# RS14100 register map
File version: 1.0
CPU: CM4 r0p1, little endian, MPU, FPU, 4 interrupt priority bits
Registers are 32-bit, read-write, reset 0x0 unless marked. A register's access mark holds for its fields unless they carry their own. Offsets are from the block's base; [hi:lo] are bit positions; {n}, {i} and the like mark numbered series; 'fields as' and 'values as' point back to an identical list.

## MCUHP_CLOCK — MCU HP (High Performance) domain contains the Cortex-M4F Processor, FPU, Debugger, MCU High Speed Interfaces, MCU HP Peripherals, MCU HP DMA and MCU/SZP shareable Interfaces
Base 0x46000000
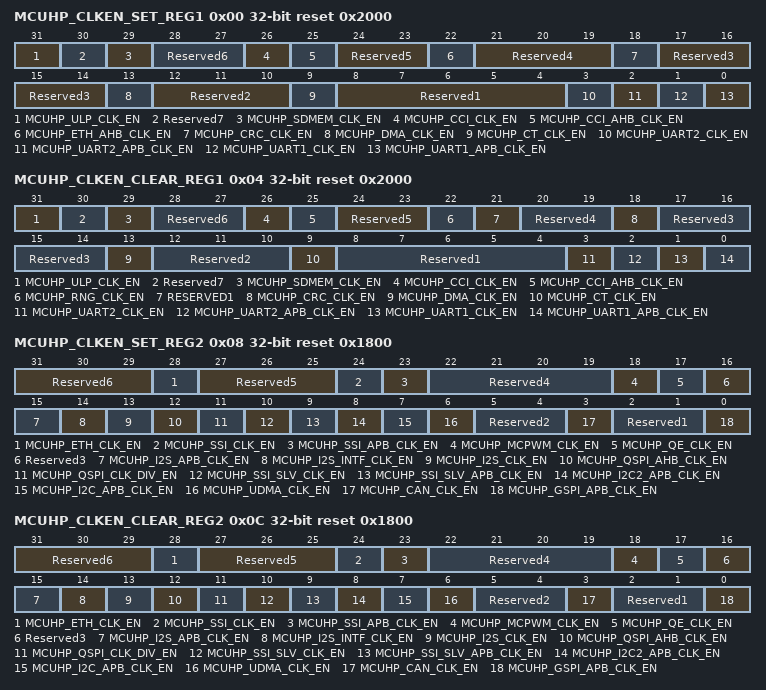
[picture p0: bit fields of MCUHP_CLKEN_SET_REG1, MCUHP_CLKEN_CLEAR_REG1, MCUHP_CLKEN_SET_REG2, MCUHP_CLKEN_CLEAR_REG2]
0x00 MCUHP_CLKEN_SET_REG1 reset 0x2000 — Clock Enable Set Register 1
  [31] MCUHP_ULP_CLK_EN wo — Writing 1 to this enables clock to MCU-ULPDomain.Writing 0 to this has no effect.
  [30] Reserved7 — It is recommended to write these bits to 0.
  [29] MCUHP_SDMEM_CLK_EN wo — Writing 1 to this enables clock to SD-MEM Controller.Writing 0 to this has no effect.
  [28:27] Reserved6 — It is recommended to write these bits to 0.
  [26] MCUHP_CCI_CLK_EN — Writing 1 to this enables clock to CCI Controller.Writing 0 to this has no effect.
  [25] MCUHP_CCI_AHB_CLK_EN — Writing 1 to this enables clock to CCI AHB Interface.Writing 0 to this has no effect.
  [24:23] Reserved5 — It is recommended to write these bits to 0.
  [22] MCUHP_ETH_AHB_CLK_EN — Writing 1 to this enables clock to Ethernet Controller AHB Interface.Writing 0 to this has no effect.
  [21:19] Reserved4 — It is recommended to write these bits to 0.
  [18] MCUHP_CRC_CLK_EN — Writing 1 to this enables clock to CRC Accelerator.Writing 0 to this has no effect.
  [17:14] Reserved3 — It is recommended to write these bits to 0.
  [13] MCUHP_DMA_CLK_EN — Writing 1 to this disables clock to DMA.Writing 0 to this has no effect.
  [12:10] Reserved2 — It is recommended to write these bits to 0.
  [9] MCUHP_CT_CLK_EN — Writing 1 to this enables clock to Configurable Timers.Writing 0 to this has no effect.
  [8:4] Reserved1 — It is recommended to write these bits to 0.
  [3] MCUHP_UART2_CLK_EN — Writing 1 to this enables clock to UART2 Controller.Writing 0 to this has no effect.
  [2] MCUHP_UART2_APB_CLK_EN — Writing 1 to this enables clock to UART2 APB Interface.Writing 0 to this has no effect.
  [1] MCUHP_UART1_CLK_EN — Writing 1 to this enables clock to UART1 Controller.Writing 0 to this has no effect.
  [0] MCUHP_UART1_APB_CLK_EN — Writing 1 to this enables clock to UART1 APB Interface.Writing 0 to this has no effect.
0x04 MCUHP_CLKEN_CLEAR_REG1 reset 0x2000 — Clock Enable Clear Register 1
  [31] MCUHP_ULP_CLK_EN — Writing 1 to this disables clock to MCU-ULPDomain.Writing 0 to this has no effect.
  [30] Reserved7 — It is recommended to write these bits to 0.
  [29] MCUHP_SDMEM_CLK_EN — Writing 1 to this disables clock to SD-MEM Controller.Writing 0 to this has no effect
  [28:27] Reserved6 — It is recommended to write these bits to 0.
  [26] MCUHP_CCI_CLK_EN — Writing 1 to this disables clock to CCI Controller.Writing 0 to this has no effect.
  [25] MCUHP_CCI_AHB_CLK_EN — Writing 1 to this disables clock to CCI AHB Interface.Writing 0 to this has no effect.
  [24:23] Reserved5 — It is recommended to write these bits to 0.
  [22] MCUHP_RNG_CLK_EN — Writing 1 to this disables clock to Random-Number-Generator.Writing 0 to this has no effect.
  [21] RESERVED1 — Writing 1 to this disables clock to Ethernet Controller AHB Interface.Writing 0 to this has no effect.
  [20:19] Reserved4 — It is recommended to write these bits to 0.
  [18] MCUHP_CRC_CLK_EN — Writing 1 to this disables clock to CRC Accelerator.Writing 0 to this has no effect.
  [17:14] Reserved3 — It is recommended to write these bits to 0.
  [13] MCUHP_DMA_CLK_EN — Writing 1 to this disables clock to DMA.Writing 0 to this has no effect
  [12:10] Reserved2 — It is recommended to write these bits to 0.
  [9] MCUHP_CT_CLK_EN — Writing 1 to this disables clock to Configurable Timers.Writing 0 to this has no effect.
  [8:4] Reserved1 — It is recommended to write these bits to 0.
  [3] MCUHP_UART2_CLK_EN — Writing 1 to this disables clock to UART2 Controller.Writing 0 to this has no effect.
  [2] MCUHP_UART2_APB_CLK_EN — Writing 1 to this disables clock to UART2 APB Interface.Writing 0 to this has no effect.
  [1] MCUHP_UART1_CLK_EN — Writing 1 to this disables clock to UART1 Controller.Writing 0 to this has no effect.
  [0] MCUHP_UART1_APB_CLK_EN — Writing 1 to this disables clock to UART1 APB Interface.Writing 0 to this has no effect.
0x08 MCUHP_CLKEN_SET_REG2 reset 0x1800 — Clock Enable Set Register 2
  [31:29] Reserved6 — It is recommended to write these bits to 0.
  [28] MCUHP_ETH_CLK_EN — Writing 1 to this enables clock to Ethernet Controller.Writing 0 to this has no effect.
  [27:25] Reserved5 — It is recommended to write these bits to 0.
  [24] MCUHP_SSI_CLK_EN — Writing 1 to this enables clock to SPI/SSI Master Controller.Writing 0 to this has no effect.
  [23] MCUHP_SSI_APB_CLK_EN — Writing 1 to this enables clock to SPI/SSI Master APN Interface.Writing 0 to this has no effect.
  [22:19] Reserved4 — It is recommended to write these bits to 0.
  [18] MCUHP_MCPWM_CLK_EN — Writing 1 to this enables clock to Motor-Control PWM.Writing 0 to this has no effect.
  [17] MCUHP_QE_CLK_EN — Writing 1 to this enables clock to Quadrature Encoder.Writing 0 to this has no effect.
  [16] Reserved3 — It is recommended to write these bits to 0.
  [15] MCUHP_I2S_APB_CLK_EN — Writing 1 to this enables clock to I2S APB Interface.Writing 0 to this has no effect.
  [14] MCUHP_I2S_INTF_CLK_EN — Writing 1 to this enables clock to I2S Interface.Writing 0 to this has no effect.
  [13] MCUHP_I2S_CLK_EN — Writing 1 to this enables clock to I2S Controller in Master Mode.Writing 0 to this has no effect.
  [12] MCUHP_QSPI_AHB_CLK_EN — Writing 1 to this enables clock to AHB Interface for SPI Flash Controller.Writing 0 to this has no effect..
  [11] MCUHP_QSPI_CLK_DIV_EN — Writing 1 to this enables clock to Clock dividers for SPI Flash Controller.Writing 0 to this has no effect.
  [10] MCUHP_SSI_SLV_CLK_EN — Writing 1 to this enables clock to SSI Slave Controller.Writing 0 to this has no effect.
  [9] MCUHP_SSI_SLV_APB_CLK_EN — Writing 1 to this enables clock to SSI Slave APB Interface.Writing 0 to this has no effect.
  [8] MCUHP_I2C2_APB_CLK_EN — Writing 1 to this enables clock to I2C-2 APB Interface.Writing 0 to this has no effect.
  [7] MCUHP_I2C_APB_CLK_EN — Writing 1 to this enables clock to I2C-1 APB Interface.Writing 0 to this has no effect.
  [6] MCUHP_UDMA_CLK_EN — Writing 1 to this enables clock to Micro-DMA.Writing 0 to this has no effect.
  [5:4] Reserved2 — It is recommended to write these bits to 0.
  [3] MCUHP_CAN_CLK_EN — Writing 1 to this enables clock to CAN Controller.Writing 0 to this has no effect.
  [2:1] Reserved1 — It is recommended to write these bits to 0
  [0] MCUHP_GSPI_APB_CLK_EN — Writing 1 to this enables clock to Generic-SPI Master APB Interface.Writing 0 to this has no effect.
0x0C MCUHP_CLKEN_CLEAR_REG2 reset 0x1800 — Clock Enable Clear Register 2
  [31:29] Reserved6 — It is recommended to write these bits to 0.
  [28] MCUHP_ETH_CLK_EN — Writing 1 to this disables clock to Ethernet Controller.Writing 0 to this has no effect.
  [27:25] Reserved5 — It is recommended to write these bits to 0.
  [24] MCUHP_SSI_CLK_EN — Writing 1 to this disables clock to SPI/SSI Master Controller.Writing 0 to this has no effect.
  [23] MCUHP_SSI_APB_CLK_EN — Writing 1 to this disables clock to SPI/SSI Master APB Interface.Writing 0 to this has no effect.
  [22:19] Reserved4 — It is recommended to write these bits to 0.
  [18] MCUHP_MCPWM_CLK_EN — Writing 1 to this disables clock to Motor-Control PWM.Writing 0 to this has no effect.
  [17] MCUHP_QE_CLK_EN — Writing 1 to this disables clock to Quadrature Encoder.Writing 0 to this has no effect.
  [16] Reserved3 — It is recommended to write these bits to 0.
  [15] MCUHP_I2S_APB_CLK_EN — Writing 1 to this disables clock to I2S APB Interface.Writing 0 to this has no effect.
  [14] MCUHP_I2S_INTF_CLK_EN — Writing 1 to this disables clock to I2S Interface.Writing 0 to this has no effect.
  [13] MCUHP_I2S_CLK_EN — Writing 1 to this disables clock to I2S Controller in Master Mode.Writing 0 to this has no effect.
  [12] MCUHP_QSPI_AHB_CLK_EN — Writing 1 to this disables clock to AHB Interface for SPI Flash Controller.Writing 0 to this has no effect.
  [11] MCUHP_QSPI_CLK_DIV_EN — Writing 1 to this disables clock to Clock dividers for SPI Flash Controller.Writing 0 to this has no effect.
  [10] MCUHP_SSI_SLV_CLK_EN — Writing 1 to this disables clock to SSI Slave Controller.Writing 0 to this has no effect.
  [9] MCUHP_SSI_SLV_APB_CLK_EN — Writing 1 to this disables clock to SSI Slave APB Interface.Writing 0 to this has no effect.
  [8] MCUHP_I2C2_APB_CLK_EN — Writing 1 to this disables clock to I2C-2 APB Interface.Writing 0 to this has no effect.
  [7] MCUHP_I2C_APB_CLK_EN — Writing 1 to this disables clock to I2C-1 APB Interface.Writing 0 to this has no effect.
  [6] MCUHP_UDMA_CLK_EN — Writing 1 to this disables clock to Micro-DMA.Writing 0 to this has no effect.
  [5:4] Reserved2 — It is recommended to write these bits to 0.
  [3] MCUHP_CAN_CLK_EN — Writing 1 to this disables clock to CAN Controller.Writing 0 to this has no effect.
  [2:1] Reserved1 — It is recommended to write these bits to 0.
  [0] MCUHP_GSPI_APB_CLK_EN — Writing 1 to this disables clock to Generic-SPI Master APB Interface.Writing 0 to this has no effect.
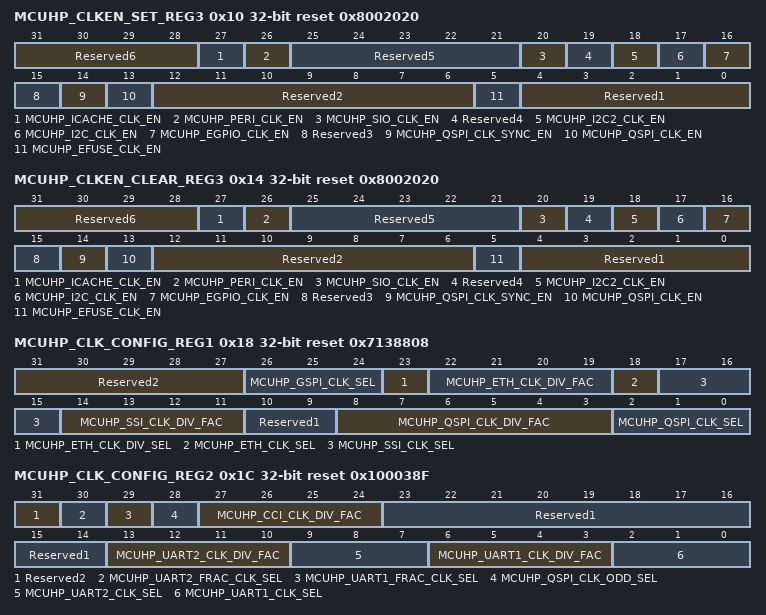
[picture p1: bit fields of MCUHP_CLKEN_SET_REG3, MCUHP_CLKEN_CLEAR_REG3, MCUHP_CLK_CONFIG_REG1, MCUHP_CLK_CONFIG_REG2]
0x10 MCUHP_CLKEN_SET_REG3 reset 0x8002020 — Clock Enable Set Register 3
  [31:28] Reserved6 — It is recommended to write these bits to 0.
  [27] MCUHP_ICACHE_CLK_EN — Writing 1 to this enables clock to Generic-SPI Master.Writing 0 to this has no effect.
  [26] MCUHP_PERI_CLK_EN — Writing 1 to this enables clock source to Peripherals.Writing 0 to this has no effect.
  [25:21] Reserved5 — It is recommended to write these bits to 0.
  [20] MCUHP_SIO_CLK_EN — Writing 1 to this enables clock to SIO Controller.Writing 0 to this has no effect.
  [19] Reserved4 — It is recommended to write these bits to 0.
  [18] MCUHP_I2C2_CLK_EN — Writing 1 to this enables clock to I2C-2 Controller.Writing 0 to this has no effect.
  [17] MCUHP_I2C_CLK_EN — Writing 1 to this enables clock to I2C-1 Controller.Writing 0 to this has no effect.
  [16] MCUHP_EGPIO_CLK_EN — Writing 1 to this enables clock to Enhanced-GPIO Controller.Writing 0 to this has no effect.
  [15] Reserved3 — It is recommended to write these bits to 0.
  [14] MCUHP_QSPI_CLK_SYNC_EN — Writing 1 to this enables SPI Flash Controller clock in synchronous with Processor Clock.Writing 0 to this has no effect.
  [13] MCUHP_QSPI_CLK_EN — Writing 1 to this enables clock to SPI Flash Controller.Writing 0 to this has no effect.
  [12:6] Reserved2 — It is recommended to write these bits to 0.
  [5] MCUHP_EFUSE_CLK_EN — Writing 1 to this enables clock to eFUSE Controller.Writing 0 to this has no effect.
  [4:0] Reserved1 — It is recommended to write these bits to 0.
0x14 MCUHP_CLKEN_CLEAR_REG3 reset 0x8002020 — Clock Enable Clear Register 3
  [31:28] Reserved6 — It is recommended to write these bits to 0.
  [27] MCUHP_ICACHE_CLK_EN — Writing 1 to this disables clock to Generic-SPI Master.Writing 0 to this has no effect.
  [26] MCUHP_PERI_CLK_EN — Writing 1 to this disables clock source to Peripherals.Writing 0 to this has no effect.
  [25:21] Reserved5 — It is recommended to write these bits to 0.
  [20] MCUHP_SIO_CLK_EN — Writing 1 to this disables clock to SIO Controller.Writing 0 to this has no effect.
  [19] Reserved4 — It is recommended to write these bits to 0.
  [18] MCUHP_I2C2_CLK_EN — Writing 1 to this disables clock to I2C-2 Controller.Writing 0 to this has no effect.
  [17] MCUHP_I2C_CLK_EN — Writing 1 to this disables clock to I2C-1 Controller.Writing 0 to this has no effect.
  [16] MCUHP_EGPIO_CLK_EN — Writing 1 to this disables clock to Enhanced-GPIO Controller.Writing 0 to this has no effect.
  [15] Reserved3 — It is recommended to write these bits to 0.
  [14] MCUHP_QSPI_CLK_SYNC_EN — Writing 1 to this disables SPI Flash Controller clock in synchronous with Processor Clock. Writing 0 to this has no effect.
  [13] MCUHP_QSPI_CLK_EN — Writing 1 to this disables clock to SPI Flash Controller.Writing 0 to this has no effect.
  [12:6] Reserved2 — It is recommended to write these bits to 0.
  [5] MCUHP_EFUSE_CLK_EN — Writing 1 to this disables clock to eFUSE Controller.Writing 0 to this has no effect.
  [4:0] Reserved1 — It is recommended to write these bits to 0.
0x18 MCUHP_CLK_CONFIG_REG1 reset 0x7138808 — Clock Configuration Register 1
  [31:27] Reserved2 — It is recommended to write these bits to 0.
  [26:24] MCUHP_GSPI_CLK_SEL — Specifies the clock source for GSPI Controller.
    0=Reserved1; 1=MCU-HP Reference Clock; 2=SoC-PLL Clock; 3=Reserved2; 4=Interface-PLL Clock; 5=Output Clock is gated; 6=Output Clock is gated; 7=Output Clock is gated
  [23] MCUHP_ETH_CLK_DIV_SEL — Selects the Divider type for Ethernet Controller.
    0=EVEN Clock Divider output is selected; 1=Clock Divider output is selected
  [22:19] MCUHP_ETH_CLK_DIV_FAC — Specifies the clock division factor for Ethernet RMII Controller.
  [18] MCUHP_ETH_CLK_SEL — Specifies the clock source for Ethernet RMII Controller.
    0=Interface-PLL Clock; 1=SoC-PLL Clock
  [17:15] MCUHP_SSI_CLK_SEL — Specifies the clock source for SPI/SSI Master.
    0=MCU-HP Reference Clock; 1=SoC-PLL Clock; 2=Reserved1; 3=Interface-PLL Clock; 4=Reserved2; 5=Reserved3; 6=Output Clock is gated; 7=Output Clock is gated
  [14:11] MCUHP_SSI_CLK_DIV_FAC — Specifies the clock division factor for for SPI/SSI Master.
  [10:9] Reserved1 — It is recommended to write these bits to 0.
  [8:3] MCUHP_QSPI_CLK_DIV_FAC — Specifies the clock division factor for SPI Flash Controller.
  [2:0] MCUHP_QSPI_CLK_SEL — Specifies the clock source for SPI Flash controller when independent clock source.
    0=MCU-HP Reference Clock; 1=Interface-PLL Clock; 2=Reserved1; 3=SoC-PLL Clock; {v}=Output Clock is gated (v=4..7)
0x1C MCUHP_CLK_CONFIG_REG2 reset 0x100038F — Clock Configuration Register 2
  [31] Reserved2 — It is recommended to write these bits to 0.
  [30] MCUHP_UART2_FRAC_CLK_SEL — Selects the Divider type for UART2 Controller. 0 - Clock Swallow output is selected 1 - Fractional Clock Divider output is selected
    0=Clock Swallow output is selected; 1=Fractional Clock Divider output is selected
  [29] MCUHP_UART1_FRAC_CLK_SEL — Selects the Divider type for UART1 Controller. 0 - Clock Swallow output is selected 1 - Fractional Clock Divider output is selected
    values as MCUHP_UART2_FRAC_CLK_SEL
  [28] MCUHP_QSPI_CLK_ODD_SEL — Selects the Divider type for SPI Flash Controller when independent clock source w.r.t Processor is selected.
    0=EVEN Clock Divider output is selected; 1=ODD Clock Divider output is selected
  [27:24] MCUHP_CCI_CLK_DIV_FAC — Specifies the clock division factor for CCI Controller.
  [23:14] Reserved1 — It is recommended to write these bits to 0.
  [13:10] MCUHP_UART2_CLK_DIV_FAC — Specifies the clock division factor for UART2 Controller.
  [9:7] MCUHP_UART2_CLK_SEL — Specifies the clock source to be used for UART2 Controller.
    0=MCU-HP Reference Clock; 1=SoC-PLL Clock; 2=Reserved1; 3=Interface-PLL Clock; 4=Reserved2; 5=Output Clock is gated; 6=Output Clock is gated; 7=Output Clock is gated
  [6:3] MCUHP_UART1_CLK_DIV_FAC — Specifies the clock division factor for UART1 Controller.
  [2:0] MCUHP_UART1_CLK_SEL — Specifies the clock source to be used for UART1 Controller.
    0=MCU-HP Reference Clock; 1=SoC-PLL Clock; 2=Reserved1; 3=Reserved2; 4=Interface-PLL Clock; 5=Output Clock is gated; 6=Output Clock is gated; 7=Output Clock is gated
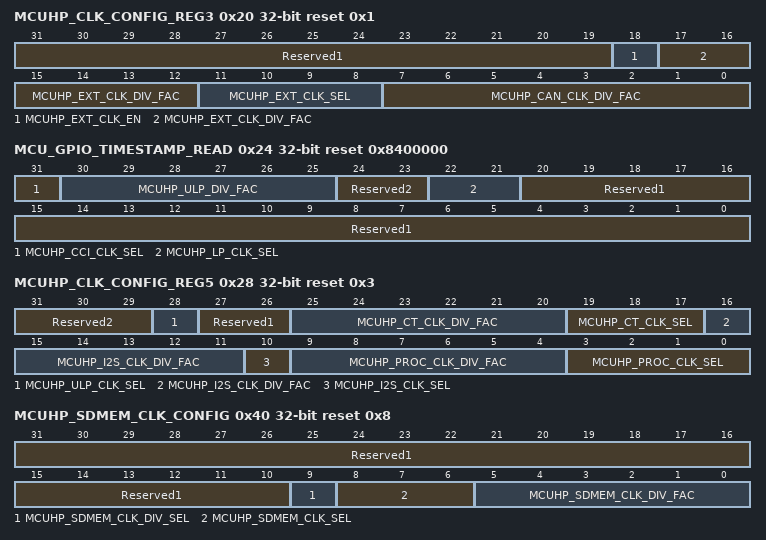
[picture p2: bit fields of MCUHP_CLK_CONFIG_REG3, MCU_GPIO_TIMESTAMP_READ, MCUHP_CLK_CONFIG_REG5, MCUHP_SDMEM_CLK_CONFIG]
0x20 MCUHP_CLK_CONFIG_REG3 reset 0x1 — Clock Configuration Register 3
  [31:19] Reserved1 — It is recommended to write these bits to 0.
  [18] MCUHP_EXT_CLK_EN — Writing 1 to this enables the External clock on GPIO PAD.Writing 0 to this disables the External clock on GPIO PAD.
  [17:12] MCUHP_EXT_CLK_DIV_FAC — Specifies the clock division factor for External Clock.
  [11:8] MCUHP_EXT_CLK_SEL — Specifies the clock source to be used for External Clock.
    0=Output Clock is Gated; 1=High Freq RC Clock source; 2=XTAL Clock source; 3=Reserved1; 4=High Freq RO Clock source; 5=Doubler Clock; 6=Reserved2; 7=Low Freq RC Clock source; 8=Low Freq XTAL Clock source; 9=Low Freq RO Clock source; 10=Interface-PLL Clock; 11=Reserved1; 12=Reserved2; 13=SoC-PLL Clock; 14=I2S-PLL Clock; 15=Reserved3
  [7:0] MCUHP_CAN_CLK_DIV_FAC — Specifies the clock division factor for CAN Controller.
0x24 MCU_GPIO_TIMESTAMP_READ reset 0x8400000 — Clock Configuration Register 4
  [31] MCUHP_CCI_CLK_SEL — Specifies the clock source to be used for Low-Power Clock.
    0=Reserved1; 1=Interface-PLL Clock
  [30:25] MCUHP_ULP_DIV_FAC — Specifies the clock division factor for MCU ULP Domain source.
  [24:23] Reserved2 — It is recommended to retain the contents by using read/modify write to this register.
  [22:21] MCUHP_LP_CLK_SEL — Specifies the clock source to be used for Low-Power Clock.
    0=Low Freq RC Clock source; 1=Low Freq XTAL Clock source; 2=Output Clock is gated; 3=Low Freq RO Clock source
  [20:0] Reserved1 — It is recommended to retain the contents by using read/modify write to this register.
0x28 MCUHP_CLK_CONFIG_REG5 reset 0x3 — Clock Configuration Register 5
  [31:29] Reserved2 — It is recommended to retain the contents by using read/modify write to this register.
  [28] MCUHP_ULP_CLK_SEL — Specifies the divider type to be selected to MCU ULP Domain source.
    0=Clock Divider output is selected; 1=Odd Clock Divider output is selected
  [27:26] Reserved1 — It is recommended to write these bits to 0.
  [25:20] MCUHP_CT_CLK_DIV_FAC — Specifies the clock division factor for Configurable Timers.
  [19:17] MCUHP_CT_CLK_SEL — Specifies the clock source to be used for Configurable Timers.
    0=MCU-HP Reference Clock; 1=Interface-PLL Clock; 2=SoC-PLL Clock; 3=Reserved1; {v}=Output Clock is gated (v=4..7)
  [16:11] MCUHP_I2S_CLK_DIV_FAC — Specifies the clock division factor for I2S Controller in Master Mode.
  [10] MCUHP_I2S_CLK_SEL — Specifies the clock source to be used for I2S Controller in Master Mode.
    0=I2S-PLL Clock; 1=Reserved1
  [9:4] MCUHP_PROC_CLK_DIV_FAC — Specifies the clock division factor for Processor Clock.
  [3:0] MCUHP_PROC_CLK_SEL — Specifies the clock source to be used for Processor.
    0=MCU-HP Reference Clock; 1=Reserved1; 2=SoC-PLL Clock; 3=Reserved2; 4=Interface-PLL Clock; 5=Low-Power Clock; 6=Reserved3; 7=Reserved4
0x40 MCUHP_SDMEM_CLK_CONFIG reset 0x8 — SDMEM Clock Configuration Register
  [31:10] Reserved1 — It is recommended to write these bits to 0.
  [9] MCUHP_SDMEM_CLK_DIV_SEL — Specifies the divider type to be selected to SDMEM Controller
    values as MCUHP_CLK_CONFIG_REG1.MCUHP_ETH_CLK_DIV_SEL
  [8:6] MCUHP_SDMEM_CLK_SEL — Specifies the clock source to be used for SD-MEM(eMMC).
    0=SoC-PLL Clock; 2=Interface-PLL Clock; 3=Reserved1; {v}=Output clock is disabled (v=4..7)
  [5:0] MCUHP_SDMEM_CLK_DIV_FAC — Specifies the clock division factor for SDMEM Controller.
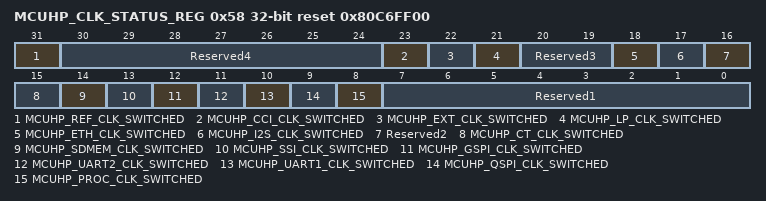
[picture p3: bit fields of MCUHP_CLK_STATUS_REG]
0x58 MCUHP_CLK_STATUS_REG reset 0x80C6FF00 — Clock Status Register for Dynamic Clock Muxes
  [31] MCUHP_REF_CLK_SWITCHED ro — Status of Dynamic Clock Mux in Reference Clock Generation
    0=Clock switching is in progress; 1=Clock got switched and output clock can be used
  [30:24] Reserved4 ro — It is recommended to write these bits to 0.
  [23] MCUHP_CCI_CLK_SWITCHED ro — Status of Dynamic Clock Mux in CCI Clock Generation
    values as MCUHP_REF_CLK_SWITCHED
  [22] MCUHP_EXT_CLK_SWITCHED ro — Status of Dynamic Clock Mux in External Clock Generation
    values as MCUHP_REF_CLK_SWITCHED
  [21] MCUHP_LP_CLK_SWITCHED ro — Status of Dynamic Clock Mux in Low-Power Clock Generation
    values as MCUHP_REF_CLK_SWITCHED
  [20:19] Reserved3 — It is recommended to write these bits to 0.
  [18] MCUHP_ETH_CLK_SWITCHED ro — Status of Dynamic Clock Mux in Ethernet RMII Clock Generation
    values as MCUHP_REF_CLK_SWITCHED
  [17] MCUHP_I2S_CLK_SWITCHED ro — Status of Dynamic Clock Mux in I2S Clock Generation
    values as MCUHP_REF_CLK_SWITCHED
  [16] Reserved2 — It is recommended to write these bits to 0.
  [15] MCUHP_CT_CLK_SWITCHED ro — Status of Dynamic Clock Mux in Configurable Timer Clock Generation
    values as MCUHP_REF_CLK_SWITCHED
  [14] MCUHP_SDMEM_CLK_SWITCHED ro — Status of Dynamic Clock Mux in SD-MEM(eMMC) Clock Generation
    values as MCUHP_REF_CLK_SWITCHED
  [13] MCUHP_SSI_CLK_SWITCHED ro — Status of Dynamic Clock Mux in SPI/SSI Master Clock Generation
    values as MCUHP_REF_CLK_SWITCHED
  [12] MCUHP_GSPI_CLK_SWITCHED ro — Status of Dynamic Clock Mux in Generic SPI Master Clock Generation
    values as MCUHP_REF_CLK_SWITCHED
  [11] MCUHP_UART2_CLK_SWITCHED ro — Status of Dynamic Clock Mux in UART2 Clock Generation
    values as MCUHP_REF_CLK_SWITCHED
  [10] MCUHP_UART1_CLK_SWITCHED ro — Status of Dynamic Clock Mux in UART1 Clock Generation
    values as MCUHP_REF_CLK_SWITCHED
  [9] MCUHP_QSPI_CLK_SWITCHED ro — Status of Dynamic Clock Mux in SPI Flash Controller Clock Generation
    values as MCUHP_REF_CLK_SWITCHED
  [8] MCUHP_PROC_CLK_SWITCHED ro — Status of Dynamic Clock Mux in Processor Clock Generation
    values as MCUHP_REF_CLK_SWITCHED
  [7:0] Reserved1 — It is recommended to write these bits to 0.
